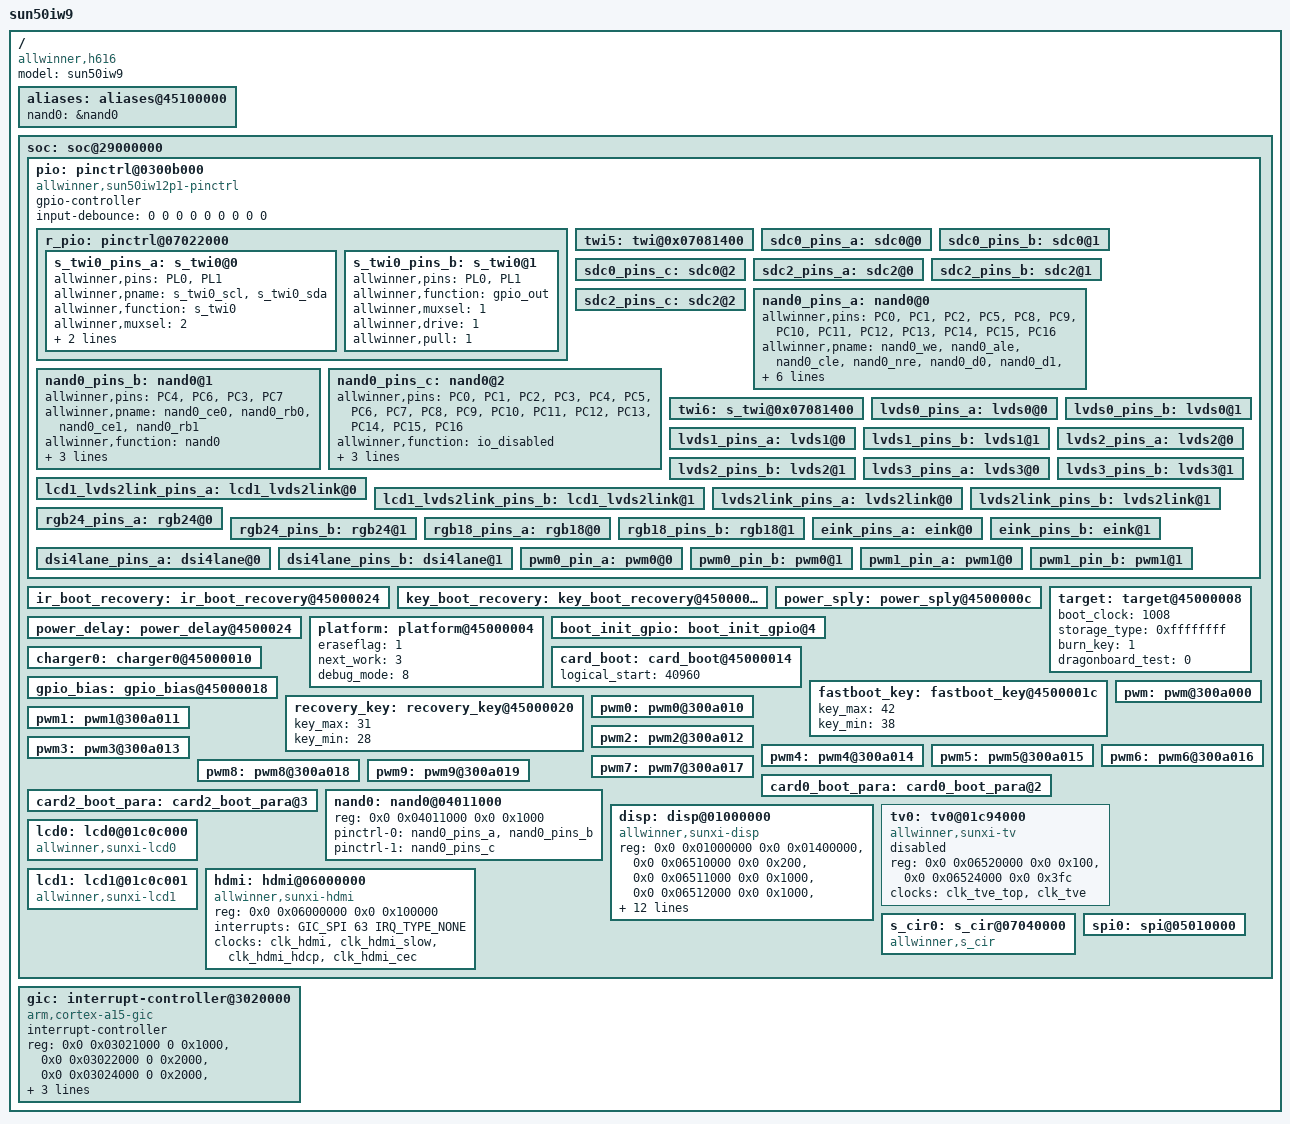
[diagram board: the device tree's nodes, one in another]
/*
 * Allwinner Technology CO., Ltd. sun50iw10p1 platform
 *
 * modify base on juno.dts
 */

/dts-v1/;
#include <dt-bindings/interrupt-controller/arm-gic.h>
#include <dt-bindings/gpio/gpio.h>
#include <dt-bindings/thermal/thermal.h>
/ {
	model = "sun50iw9";
	compatible = "allwinner,h616", "arm,sun50iw9p1";
	#address-cells = <2>;
	#size-cells = <2>;
	aliases:aliases@45100000 {
		nand0=&nand0;
	};
	soc: soc@29000000 {
		#address-cells = <2>;
		#size-cells = <2>;


		pio: pinctrl@0300b000 {
			compatible = "allwinner,sun50iw12p1-pinctrl";
			device_type = "pio";
			gpio-controller;
			#size-cells = <0>;
			#gpio-cells = <6>;
			/* takes the debounce time in usec as argument */
			input-debounce = <0 0 0 0 0 0 0 0 0>;
			r_pio: pinctrl@07022000 {

				s_twi0_pins_a: s_twi0@0 {
					allwinner,pins = "PL0", "PL1";
					allwinner,pname = "s_twi0_scl", "s_twi0_sda";
					allwinner,function = "s_twi0";
					allwinner,muxsel = <2>;
					allwinner,drive = <1>;
					allwinner,pull = <1>;
				};

				s_twi0_pins_b: s_twi0@1 {
					allwinner,pins = "PL0", "PL1";
					allwinner,function = "gpio_out";
					allwinner,muxsel = <1>;
					allwinner,drive = <1>;
					allwinner,pull = <1>;
				};
			};

			twi5: twi@0x07081400{
				#address-cells = <1>;
				#size-cells = <0>;
			};

			sdc0_pins_a: sdc0@0 {
			};

			sdc0_pins_b: sdc0@1 {
			};

			sdc0_pins_c: sdc0@2 {
			};

			sdc2_pins_a: sdc2@0 {
			};

			sdc2_pins_b: sdc2@1 {
			};

			sdc2_pins_c: sdc2@2 {
			};

			nand0_pins_a: nand0@0 {
				allwinner,pins = "PC0", "PC1", "PC2", "PC5",
						 "PC8", "PC9", "PC10", "PC11",
						 "PC12", "PC13", "PC14", "PC15",
						 "PC16";
				allwinner,pname= "nand0_we", "nand0_ale","nand0_cle", "nand0_nre",
						 "nand0_d0", "nand0_d1", "nand0_d2", "nand0_d3",
						 "nand0_d4", "nand0_d5", "nand0_d6", "nand0_d7",
						 "nand0_ndqs";
				allwinner,function = "nand0";
				allwinner,muxsel = <2>;
				allwinner,drive = <1>;
				allwinner,pull = <0>;

			};

			nand0_pins_b: nand0@1 {
				allwinner,pins = "PC4", "PC6", "PC3", "PC7";
				allwinner,pname= "nand0_ce0", "nand0_rb0", "nand0_ce1", "nand0_rb1";
				allwinner,function = "nand0";
				allwinner,muxsel = <2>;
				allwinner,drive = <1>;
				allwinner,pull = <1>;	/* only RB&CE should be pulled up */
			};

			nand0_pins_c: nand0@2 {
				allwinner,pins = "PC0", "PC1", "PC2", "PC3",
						 "PC4", "PC5", "PC6", "PC7",
						 "PC8", "PC9", "PC10", "PC11",
						 "PC12", "PC13", "PC14", "PC15",
						 "PC16";
				allwinner,function = "io_disabled";
				allwinner,muxsel = <7>;
				allwinner,drive = <1>;
				allwinner,pull = <0>;
			};

			twi6: s_twi@0x07081400 {
			};
			lvds0_pins_a: lvds0@0 {
			};
			lvds0_pins_b: lvds0@1 {
			};
			lvds1_pins_a: lvds1@0 {
			};
			lvds1_pins_b: lvds1@1 {
			};
			lvds2_pins_a: lvds2@0 {
			};
			lvds2_pins_b: lvds2@1 {
			};
			lvds3_pins_a: lvds3@0 {
			};
			lvds3_pins_b: lvds3@1 {
			};
			lcd1_lvds2link_pins_a: lcd1_lvds2link@0 {
			};
			lcd1_lvds2link_pins_b: lcd1_lvds2link@1 {
			};
			lvds2link_pins_a: lvds2link@0 {
			};
			lvds2link_pins_b: lvds2link@1 {
			};
			rgb24_pins_a: rgb24@0 {
			};
			rgb24_pins_b: rgb24@1 {
			};
			rgb18_pins_a: rgb18@0 {
			};
			rgb18_pins_b: rgb18@1 {
			};
			eink_pins_a: eink@0 {
			};
			eink_pins_b: eink@1 {
			};
			dsi4lane_pins_a: dsi4lane@0 {
			};
			dsi4lane_pins_b: dsi4lane@1 {
			};
			pwm0_pin_a: pwm0@0 {
			};

			pwm0_pin_b: pwm0@1 {
			};

			pwm1_pin_a: pwm1@0 {
			};

			pwm1_pin_b: pwm1@1 {
			};
		};

		ir_boot_recovery:ir_boot_recovery@45000024 {
			device_type = "ir_boot_recovery";
		};

		key_boot_recovery:key_boot_recovery@45000028 {
			device_type = "key_boot_recovery";
		};
		power_sply:power_sply@4500000c {
			device_type = "power_sply";

		};

		power_delay:power_delay@4500024 {
			device_type = "power_delay";
		};

		platform:platform@45000004 {
			device_type = "platform";

		};

		boot_init_gpio:boot_init_gpio@4 {
			device_type = "boot_init_gpio";

		};
		target:target@45000008 {
			device_type = "target";

		};

		charger0:charger0@45000010 {
			device_type = "charger0";

		};
		card_boot:card_boot@45000014 {
			device_type = "card_boot";
			logical_start   = <40960>;
			/* sprite_gpio0 = <&pio PH 6 1 0xffffffff 0xffffffff 1>; */
		};

		gpio_bias:gpio_bias@45000018 {
			device_type = "gpio_bias";
		};

		fastboot_key:fastboot_key@4500001c {
			device_type = "fastboot_key";
			key_max = <42>;
			key_min = <38>;
		};

		recovery_key:recovery_key@45000020 {
			device_type = "recovery_key";
			key_max = <31>;
			key_min = <28>;
		};

		pwm: pwm@300a000 {
		};

		pwm0: pwm0@300a010 {
		};

		pwm1: pwm1@300a011 {
		};

		pwm2: pwm2@300a012 {
		};

		pwm3: pwm3@300a013 {
		};

		pwm4: pwm4@300a014 {
		};

		pwm5: pwm5@300a015 {
		};

		pwm6: pwm6@300a016 {
		};

		pwm7: pwm7@300a017 {
		};

		pwm8: pwm8@300a018 {
		};

		pwm9: pwm9@300a019 {
		};

		card0_boot_para:card0_boot_para@2 {
			device_type = "card0_boot_para";
		};

		card2_boot_para:card2_boot_para@3 {
			device_type = "card2_boot_para";
		};

		nand0:nand0@04011000 {
			device_type = "nand0";
			reg = <0x0 0x04011000 0x0 0x1000>;/* nand0 */
			pinctrl-0 = <&nand0_pins_a &nand0_pins_b>;
			pinctrl-1 = <&nand0_pins_c>;
		};

		disp: disp@01000000 {
			compatible = "allwinner,sunxi-disp";
			reg = <0x0 0x01000000 0x0 0x01400000>,/*de*/
			<0x0 0x06510000 0x0 0x200>,/*display_if_top*/
			<0x0 0x06511000 0x0 0x1000>,/*tcon_lcd0*/
			<0x0 0x06512000 0x0 0x1000>,/*tcon_lcd1*/
			<0x0 0x06515000 0x0 0x1000>,/*tcon_tv0*/
			<0x0 0x06516000 0x0 0x1000>;/*tcon_tv1*/
			interrupts = <GIC_SPI 88 IRQ_TYPE_LEVEL_HIGH>, /*DE*/
			<GIC_SPI 64 IRQ_TYPE_LEVEL_HIGH>, /*tcon_lcd0*/
			<GIC_SPI 65 IRQ_TYPE_LEVEL_HIGH>, /*tcon_lcd1*/
			<GIC_SPI 66 IRQ_TYPE_LEVEL_HIGH>, /*tcon_tv0*/
			<GIC_SPI 67 IRQ_TYPE_LEVEL_HIGH>; /*tcon_tv1*/
			clocks = <&clk_de>,
				 <&clk_display_top>,
				 <&clk_tcon_lcd>,
				 <&clk_tcon_lcd1>,
				 <&clk_tcon_tv>,
				 <&clk_tcon_tv1>,
				 <&clk_lvds>;
			boot_disp = <0>;
			fb_base = <0>;
			status = "okay";
		};

		tv0: tv0@01c94000 {
			compatible = "allwinner,sunxi-tv";
			reg = <0x0 0x06520000 0x0 0x100>,
				<0x0 0x06524000 0x0 0x3fc>;
			clocks = <&clk_tve_top>,<&clk_tve>;
			device_type = "tv0";
			pinctrl-names = "active","sleep";
			status = "disabled";
		};

		lcd0: lcd0@01c0c000 {
			compatible = "allwinner,sunxi-lcd0";
			pinctrl-names = "active","sleep";
			status = "okay";
		};

		lcd1: lcd1@01c0c001 {
			compatible = "allwinner,sunxi-lcd1";
			pinctrl-names = "active","sleep";
			status = "okay";
		};

		hdmi: hdmi@06000000 {
			compatible = "allwinner,sunxi-hdmi";
			reg = <0x0 0x06000000 0x0 0x100000>;
			interrupts = <GIC_SPI 63 IRQ_TYPE_NONE>;
			clocks = <&clk_hdmi>,<&clk_hdmi_slow>,<&clk_hdmi_hdcp>,<&clk_hdmi_cec>;
			status = "okay";
		};

		s_cir0: s_cir@07040000 {
			compatible = "allwinner,s_cir";
		};
		spi0: spi@05010000 {
			#address-cells = <1>;
			#size-cells = <0>;
		};
	};

	gic: interrupt-controller@3020000 {
		compatible = "arm,cortex-a15-gic", "arm,cortex-a9-gic";
		#interrupt-cells = <3>;
		#address-cells = <0>;
		device_type = "gic";
		interrupt-controller;
		reg = <0x0 0x03021000 0 0x1000>, /* GIC Dist */
		      <0x0 0x03022000 0 0x2000>, /* GIC CPU */
		      <0x0 0x03024000 0 0x2000>, /* GIC VCPU Control */
		      <0x0 0x03026000 0 0x2000>; /* GIC VCPU */
		interrupts = <GIC_PPI 9 0xf04>;  /* GIC Maintenence IRQ */
		interrupt-parent = <&gic>;
	};

};

&platform{
	device_type = "platform";
	eraseflag   = <1>;
	next_work   = <3>;
	debug_mode  = <8>;
};

&target{
	device_type = "target";
	boot_clock = <1008>;	/*CPU boot frequency, Unit: MHz*/
	storage_type = <0xffffffff>; /*boot medium, 0-nand, 1-card0, 2-card2, -1(defualt)auto scan*/
	burn_key = <1>;		/*1:support burn key; 0:not support burn key*/
	dragonboard_test = <0>;	/*1:support card boot dragonboard; 0:not support card boot dragonboard*/
};
#include "sun50iw9p1-clk.dtsi"
#include ".board-uboot.dts"
